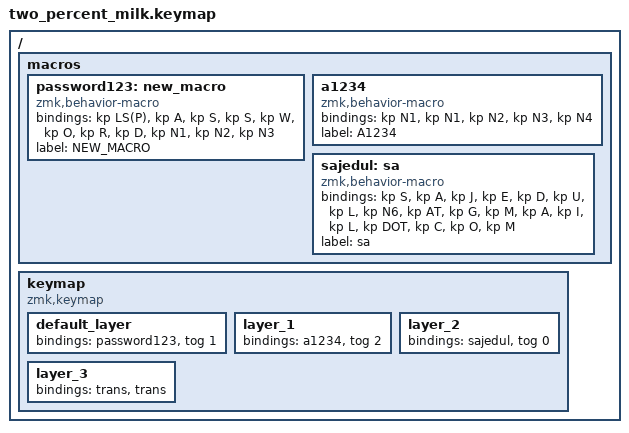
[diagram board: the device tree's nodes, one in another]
/*
 * Copyright (c) 2022 The ZMK Contributors
 *
 * SPDX-License-Identifier: MIT
 */

#include <behaviors.dtsi>
#include <dt-bindings/zmk/keys.h>

/ {
    macros {
        password123: new_macro {
            compatible = "zmk,behavior-macro";
            #binding-cells = <0>;
            bindings = <&kp LS(P) &kp A &kp S &kp S &kp W &kp O &kp R &kp D &kp N1 &kp N2 &kp N3>;
            label = "NEW_MACRO";
        };

        a1234: a1234 {
            compatible = "zmk,behavior-macro";
            #binding-cells = <0>;
            bindings = <&kp N1 &kp N1 &kp N2 &kp N3 &kp N4>;
            label = "A1234";
        };

        sajedul: sa {
            compatible = "zmk,behavior-macro";
            #binding-cells = <0>;
            bindings = <&kp S &kp A &kp J &kp E &kp D &kp U &kp L &kp N6 &kp AT &kp G &kp M &kp A &kp I &kp L &kp DOT &kp C &kp O &kp M>;
            label = "sa";
        };
    };

    keymap {
        compatible = "zmk,keymap";

        default_layer {
            bindings = <
&password123  &tog 1
            >;
        };

        layer_1 {
            bindings = <
&a1234  &tog 2
            >;
        };

        layer_2 {
            bindings = <
&sajedul  &tog 0
            >;
        };

        layer_3 {
            bindings = <
&trans  &trans
            >;
        };
    };
};
